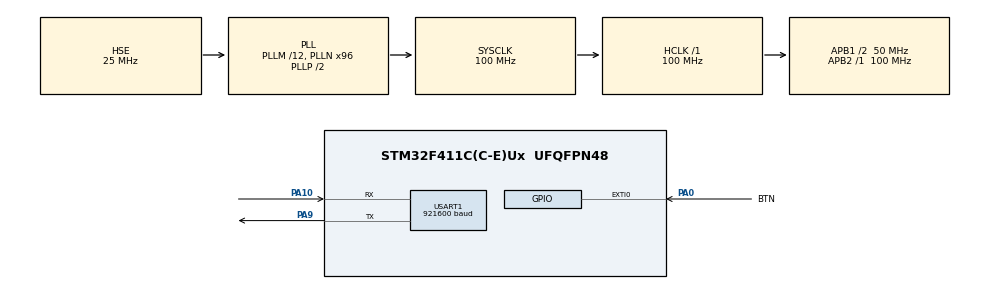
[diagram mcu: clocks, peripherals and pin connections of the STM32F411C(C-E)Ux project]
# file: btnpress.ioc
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Mcu.Family=STM32F4
Mcu.Name=STM32F411C(C-E)Ux
Mcu.Package=UFQFPN48
NVIC.EXTI0_IRQn=true\:0\:0\:false\:false\:true\:true\:true\:true
NVIC.PriorityGroup=NVIC_PRIORITYGROUP_4
NVIC.TIM3_IRQn=true\:0\:0\:false\:false\:true\:true\:true\:true
PA0-WKUP.GPIO_Label=BTN
PA0-WKUP.GPIO_ModeDefaultEXTI=GPIO_MODE_IT_RISING_FALLING
PA0-WKUP.GPIO_PuPd=GPIO_PULLUP
PA0-WKUP.Signal=GPXTI0
PA10.Mode=Asynchronous
PA10.Signal=USART1_RX
PA13.Mode=Serial_Wire
PA13.Signal=SYS_JTMS-SWDIO
PA14.Mode=Serial_Wire
PA14.Signal=SYS_JTCK-SWCLK
PA9.Mode=Asynchronous
PA9.Signal=USART1_TX
PH0\ -\ OSC_IN.Mode=HSE-External-Oscillator
PH0\ -\ OSC_IN.Signal=RCC_OSC_IN
PH1\ -\ OSC_OUT.Mode=HSE-External-Oscillator
PH1\ -\ OSC_OUT.Signal=RCC_OSC_OUT
ProjectManager.HeapSize=0x200
ProjectManager.StackSize=0x400
ProjectManager.TargetToolchain=STM32CubeIDE
RCC.48MHZClocksFreq_Value=50000000
RCC.AHBFreq_Value=100000000
RCC.APB1CLKDivider=RCC_HCLK_DIV2
RCC.APB1Freq_Value=50000000
RCC.APB1TimFreq_Value=100000000
RCC.APB2Freq_Value=100000000
RCC.APB2TimFreq_Value=100000000
RCC.CortexFreq_Value=100000000
RCC.HCLKFreq_Value=100000000
RCC.HSE_VALUE=25000000
RCC.HSI_VALUE=16000000
RCC.LSE_VALUE=32768
RCC.PLLM=12
RCC.PLLN=96
RCC.PLLSourceVirtual=RCC_PLLSOURCE_HSE
RCC.SYSCLKFreq_VALUE=100000000
RCC.SYSCLKSource=RCC_SYSCLKSOURCE_PLLCLK
RCC.VCOOutputFreq_Value=200000000
TIM3.CounterMode=TIM_COUNTERMODE_DOWN
TIM3.Period=100
TIM3.Prescaler=9999
TIM3.TIM_MasterOutputTrigger=TIM_TRGO_UPDATE
USART1.BaudRate=921600
USART1.VirtualMode=VM_ASYNC
VP_TIM3_VS_ClockSourceINT.Mode=Internal
board=custom

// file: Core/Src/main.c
/* USER CODE BEGIN Header */
/**
  ******************************************************************************
  * @file           : main.c
  * @brief          : Main program body
  ******************************************************************************
  * @attention
  *
  * Copyright (c) 2022 STMicroelectronics.
  * All rights reserved.
  *
  * This software is licensed under terms that can be found in the LICENSE file
  * in the root directory of this software component.
  * If no LICENSE file comes with this software, it is provided AS-IS.
  *
  ******************************************************************************
  */
/* USER CODE END Header */
#include "main.h"

/* USER CODE BEGIN Includes */
#include "stdio.h"
/* USER CODE END Includes */

TIM_HandleTypeDef htim3;

UART_HandleTypeDef huart1;

/* USER CODE BEGIN PV */

uint32_t btn_press_time = 0, btn_release_time = 0;

/* USER CODE END PV */

void SystemClock_Config(void);
static void MX_GPIO_Init(void);
static void MX_USART1_UART_Init(void);
static void MX_TIM3_Init(void);

/* USER CODE BEGIN 0 */

// Send printf to uart1
int _write(int fd, char* ptr, int len) {
  HAL_StatusTypeDef hstatus;

  if (fd == 1 || fd == 2) {
    hstatus = HAL_UART_Transmit(&huart1, (uint8_t *) ptr, len, HAL_MAX_DELAY);
    if (hstatus == HAL_OK)
      return len;
    else
      return -1;
  }
  return -1;
}

void HAL_GPIO_EXTI_Callback(uint16_t GPIO_Pin) {
	if (GPIO_Pin == BTN_Pin) // If the button
	{
		GPIO_PinState state = HAL_GPIO_ReadPin(BTN_GPIO_Port, BTN_Pin);

		if (state == GPIO_PIN_RESET) {  // Butten was pressed
			btn_press_time = HAL_GetTick();
		} else {						// Button was released

		}

	}
}

/* USER CODE END 0 */

int main(void)
{

  /* MCU Configuration--------------------------------------------------------*/

  /* Reset of all peripherals, Initializes the Flash interface and the Systick. */
  HAL_Init();

  /* Configure the system clock */
  SystemClock_Config();

  /* Initialize all configured peripherals */
  MX_GPIO_Init();
  MX_USART1_UART_Init();
  MX_TIM3_Init();
  /* USER CODE BEGIN 2 */

  DBG("Starting!");

  /* USER CODE END 2 */

  /* Infinite loop */
  while (1)
  {

  }
}

void SystemClock_Config(void)
{
  RCC_OscInitTypeDef RCC_OscInitStruct = {0};
  RCC_ClkInitTypeDef RCC_ClkInitStruct = {0};

  /** Configure the main internal regulator output voltage
  */
  __HAL_RCC_PWR_CLK_ENABLE();
  __HAL_PWR_VOLTAGESCALING_CONFIG(PWR_REGULATOR_VOLTAGE_SCALE1);

  /** Initializes the RCC Oscillators according to the specified parameters
  * in the RCC_OscInitTypeDef structure.
  */
  RCC_OscInitStruct.OscillatorType = RCC_OSCILLATORTYPE_HSE;
  RCC_OscInitStruct.HSEState = RCC_HSE_ON;
  RCC_OscInitStruct.PLL.PLLState = RCC_PLL_ON;
  RCC_OscInitStruct.PLL.PLLSource = RCC_PLLSOURCE_HSE;
  RCC_OscInitStruct.PLL.PLLM = 12;
  RCC_OscInitStruct.PLL.PLLN = 96;
  RCC_OscInitStruct.PLL.PLLP = RCC_PLLP_DIV2;
  RCC_OscInitStruct.PLL.PLLQ = 4;
  if (HAL_RCC_OscConfig(&RCC_OscInitStruct) != HAL_OK)
  {
    Error_Handler();
  }

  /** Initializes the CPU, AHB and APB buses clocks
  */
  RCC_ClkInitStruct.ClockType = RCC_CLOCKTYPE_HCLK|RCC_CLOCKTYPE_SYSCLK
                              |RCC_CLOCKTYPE_PCLK1|RCC_CLOCKTYPE_PCLK2;
  RCC_ClkInitStruct.SYSCLKSource = RCC_SYSCLKSOURCE_PLLCLK;
  RCC_ClkInitStruct.AHBCLKDivider = RCC_SYSCLK_DIV1;
  RCC_ClkInitStruct.APB1CLKDivider = RCC_HCLK_DIV2;
  RCC_ClkInitStruct.APB2CLKDivider = RCC_HCLK_DIV1;

  if (HAL_RCC_ClockConfig(&RCC_ClkInitStruct, FLASH_LATENCY_3) != HAL_OK)
  {
    Error_Handler();
  }
}

static void MX_TIM3_Init(void)
{

  TIM_ClockConfigTypeDef sClockSourceConfig = {0};
  TIM_MasterConfigTypeDef sMasterConfig = {0};

  htim3.Instance = TIM3;
  htim3.Init.Prescaler = 9999;
  htim3.Init.CounterMode = TIM_COUNTERMODE_DOWN;
  htim3.Init.Period = 100;
  htim3.Init.ClockDivision = TIM_CLOCKDIVISION_DIV1;
  htim3.Init.AutoReloadPreload = TIM_AUTORELOAD_PRELOAD_DISABLE;
  if (HAL_TIM_Base_Init(&htim3) != HAL_OK)
  {
    Error_Handler();
  }
  sClockSourceConfig.ClockSource = TIM_CLOCKSOURCE_INTERNAL;
  if (HAL_TIM_ConfigClockSource(&htim3, &sClockSourceConfig) != HAL_OK)
  {
    Error_Handler();
  }
  sMasterConfig.MasterOutputTrigger = TIM_TRGO_UPDATE;
  sMasterConfig.MasterSlaveMode = TIM_MASTERSLAVEMODE_DISABLE;
  if (HAL_TIMEx_MasterConfigSynchronization(&htim3, &sMasterConfig) != HAL_OK)
  {
    Error_Handler();
  }

}

static void MX_USART1_UART_Init(void)
{

  huart1.Instance = USART1;
  huart1.Init.BaudRate = 921600;
  huart1.Init.WordLength = UART_WORDLENGTH_8B;
  huart1.Init.StopBits = UART_STOPBITS_1;
  huart1.Init.Parity = UART_PARITY_NONE;
  huart1.Init.Mode = UART_MODE_TX_RX;
  huart1.Init.HwFlowCtl = UART_HWCONTROL_NONE;
  huart1.Init.OverSampling = UART_OVERSAMPLING_16;
  if (HAL_UART_Init(&huart1) != HAL_OK)
  {
    Error_Handler();
  }

}

static void MX_GPIO_Init(void)
{
  GPIO_InitTypeDef GPIO_InitStruct = {0};

  /* GPIO Ports Clock Enable */
  __HAL_RCC_GPIOH_CLK_ENABLE();
  __HAL_RCC_GPIOA_CLK_ENABLE();

  /*Configure GPIO pin : BTN_Pin */
  GPIO_InitStruct.Pin = BTN_Pin;
  GPIO_InitStruct.Mode = GPIO_MODE_IT_RISING_FALLING;
  GPIO_InitStruct.Pull = GPIO_PULLUP;
  HAL_GPIO_Init(BTN_GPIO_Port, &GPIO_InitStruct);

  /* EXTI interrupt init*/
  HAL_NVIC_SetPriority(EXTI0_IRQn, 0, 0);
  HAL_NVIC_EnableIRQ(EXTI0_IRQn);

}

void Error_Handler(void)
{
  __disable_irq();
  while (1)
  {
  }
}
